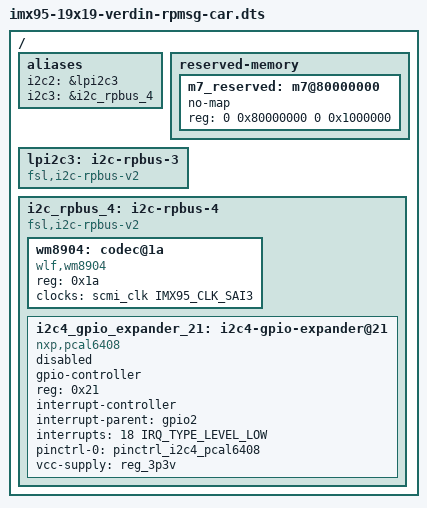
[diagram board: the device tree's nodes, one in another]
// SPDX-License-Identifier: (GPL-2.0+ OR MIT)
/*
 * Copyright 2024 NXP
 */

#include "imx95-19x19-verdin.dts"

/delete-node/ &lpi2c3;
/delete-node/ &lpi2c4;

/ {
	aliases {
		i2c2 = &lpi2c3;
		i2c3 = &i2c_rpbus_4;
	};

	reserved-memory {
		m7_reserved: m7@80000000 {
			no-map;
			reg = <0 0x80000000 0 0x1000000>;
		};
	};

	lpi2c3: i2c-rpbus-3 {
		compatible = "fsl,i2c-rpbus-v2";
		#address-cells = <1>;
		#size-cells = <0>;
		status = "okay";
	};

	i2c_rpbus_4: i2c-rpbus-4 {
		compatible = "fsl,i2c-rpbus-v2";
		#address-cells = <1>;
		#size-cells = <0>;
		status = "okay";

		wm8904: codec@1a {
			#sound-dai-cells = <0>;
			compatible = "wlf,wm8904";
			reg = <0x1a>;
			clocks = <&scmi_clk IMX95_CLK_SAI3>;
			clock-names = "mclk";
		};

		i2c4_gpio_expander_21: i2c4-gpio-expander@21 {
			compatible = "nxp,pcal6408";
			#gpio-cells = <2>;
			gpio-controller;
			reg = <0x21>;
			interrupt-controller;
			#interrupt-cells = <2>;
			interrupt-parent = <&gpio2>;
			interrupts = <18 IRQ_TYPE_LEVEL_LOW>;
			pinctrl-names = "default";
			pinctrl-0 = <&pinctrl_i2c4_pcal6408>;
			vcc-supply = <&reg_3p3v>;
			status = "disabled";
		};
	};
};
